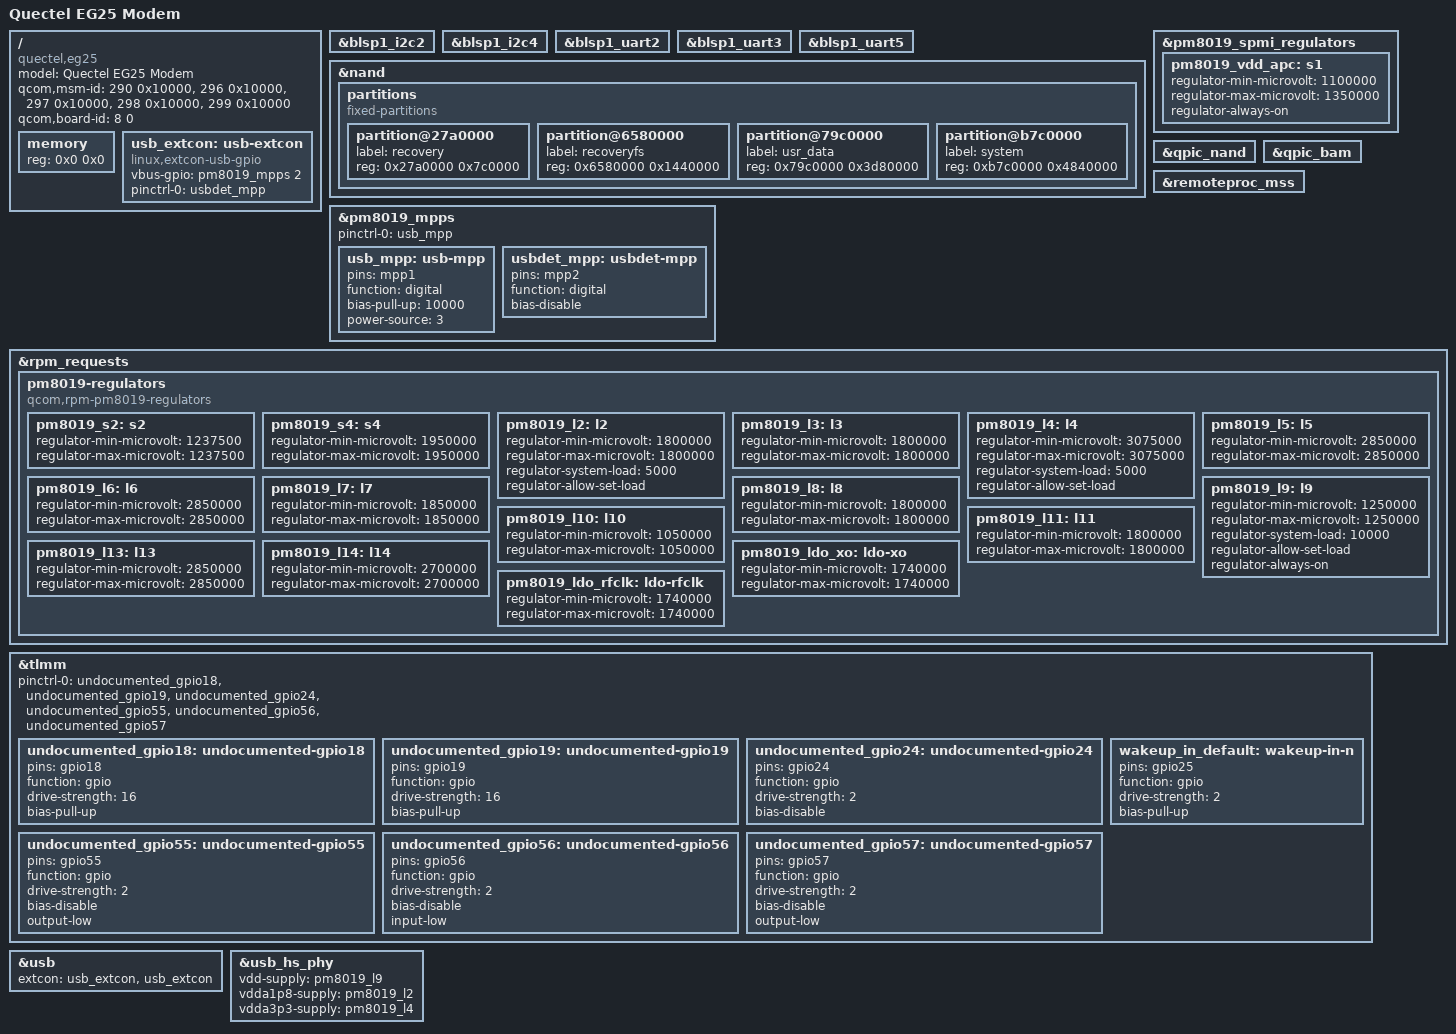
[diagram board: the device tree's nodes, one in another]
// SPDX-License-Identifier: GPL-2.0
/*
 * Copyright (c) 2020, Konrad Dybcio <konrad.dybcio@somainline.org>
 */
#include "qcom-mdm9607.dtsi"
#include "qcom-pm8019.dtsi"
#include <dt-bindings/gpio/gpio.h>
#include <dt-bindings/input/input.h>
#include <dt-bindings/pinctrl/qcom,pmic-gpio.h>

/ {
	model = "Quectel EG25 Modem";
	compatible = "quectel,eg25", "qcom,mdm9607";
	qcom,msm-id = <290 0x10000>, <296 0x10000>, <297 0x10000>, <298 0x10000>, <299 0x10000>;
	qcom,board-id = <8 0>;

	memory {
		device_type = "memory";
		reg = <0x0 0x0>;
	};

	usb_extcon: usb-extcon {
		compatible = "linux,extcon-usb-gpio";
		vbus-gpio = <&pm8019_mpps 2 GPIO_ACTIVE_HIGH>;
		pinctrl-names = "default";
		pinctrl-0 = <&usbdet_mpp>;
	};
};

&blsp1_i2c2 {
	status = "okay";
};

&blsp1_i2c4 {
	status = "okay";

	/delete-property/ pinctrl-names;
	/delete-property/ pinctrl-0;
};

&blsp1_uart2 {
	status = "okay";
};

&blsp1_uart3 {
	status = "okay";
};

/* Debug UART */
&blsp1_uart5 {
	status = "okay";
};

&nand {
	partitions {
		compatible = "fixed-partitions";
		#address-cells = <1>;
		#size-cells = <1>;

		partition@27a0000 {
			label = "recovery";
			reg = <0x27a0000 0x7c0000>;
		};

		partition@6580000 {
			label = "recoveryfs";
			reg = <0x6580000 0x1440000>;
		};

		partition@79c0000 {
			label = "usr_data";
			reg = <0x79c0000 0x3d80000>;
		};

		partition@b7c0000 {
			label = "system";
			reg = <0xb7c0000 0x4840000>;
		};
	};
};

&pm8019_mpps {
	pinctrl-names = "default";
	pinctrl-0 = <&usb_mpp>;

	usb_mpp: usb-mpp {
		pins = "mpp1";
		function = "digital";
		bias-pull-up = <10000>;

		power-source = <3>; /* 1.8V (L11) */
	};

	usbdet_mpp: usbdet-mpp {
		pins = "mpp2";
		function = "digital";
		bias-disable;
	};
};

&pm8019_spmi_regulators {
	pm8019_vdd_apc: s1 {
		/*
		 * This regulator has a minimum voltage of
		 * 1050uV on this board, but it has the "normal
		 * idle" value pinned at 1100uV and since undervolting
		 * the CPU all the time isn't generally a wise idea, pin
		 * it at 1100uV until we have proper voltage management.
		 */
		regulator-min-microvolt = <1100000>;
		regulator-max-microvolt = <1350000>;
		regulator-always-on; /* We should never let the CPU unplug itself! */
	};
};

/* NAND ID: 0x1590aaad | 256MiB | 4-bit ECC */
&qpic_nand {
	status = "okay";
};

&qpic_bam {
	status = "okay";
};

&remoteproc_mss {
	status = "okay";
};

&rpm_requests {
	pm8019-regulators {
		compatible = "qcom,rpm-pm8019-regulators";

		/* S1 is managed by CPR over SPMI */

		pm8019_s2: s2 {
			regulator-min-microvolt = <1237500>; //750000
			regulator-max-microvolt = <1237500>;
		};

		/* S3 is managed by RPMPD */

		pm8019_s4: s4 {
			regulator-min-microvolt = <1950000>; //1800000
			regulator-max-microvolt = <1950000>;
		};

		/* L1 seems inaccessible from SPMI? 1250000-1250000 uV */

		pm8019_l2: l2 {
			regulator-min-microvolt = <1800000>;
			regulator-max-microvolt = <1800000>;
			regulator-system-load = <5000>;
			regulator-allow-set-load;
		};

		pm8019_l3: l3 {
			regulator-min-microvolt = <1800000>;
			regulator-max-microvolt = <1800000>;
		};

		pm8019_l4: l4 {
			regulator-min-microvolt = <3075000>;
			regulator-max-microvolt = <3075000>;
			regulator-system-load = <5000>;
			regulator-allow-set-load;
		};

		pm8019_l5: l5 {
			regulator-min-microvolt = <2850000>; //1700000
			regulator-max-microvolt = <2850000>;
		};

		pm8019_l6: l6 {
			regulator-min-microvolt = <2850000>; //1700000
			regulator-max-microvolt = <2850000>;
		};

		pm8019_l7: l7 {
			regulator-min-microvolt = <1850000>; //1700000
			regulator-max-microvolt = <1850000>;
		};

		pm8019_l8: l8 {
			regulator-min-microvolt = <1800000>;
			regulator-max-microvolt = <1800000>;
		};

		/* L9 seems inaccessible from SPMI? 1200000-1250000 uV */
		pm8019_l9: l9 {
			regulator-min-microvolt = <1250000>;
			regulator-max-microvolt = <1250000>;
			regulator-system-load = <10000>;
			regulator-allow-set-load;
			regulator-always-on;
		};

		/* L10 seems inaccessible from SPMI? 1050000-1050000 uV */
		pm8019_l10: l10 {
			regulator-min-microvolt = <1050000>;
			regulator-max-microvolt = <1050000>;
		};

		pm8019_l11: l11 {
			regulator-min-microvolt = <1800000>;
			regulator-max-microvolt = <1800000>;
		};

		/* L12 is managed by RPMPD */

		pm8019_l13: l13 {
			regulator-min-microvolt = <2850000>; //1800000
			regulator-max-microvolt = <2850000>;
		};

		pm8019_l14: l14 {
			regulator-min-microvolt = <2700000>; //2650000
			regulator-max-microvolt = <2700000>;
		};

		/*
		 * These two are theoretically managed by SPMI
		 * and theoretically disabled over there, but they
		 * are up in LK, so let's vote for them here too.
		 */

		pm8019_ldo_xo: ldo-xo {
			regulator-min-microvolt = <1740000>;
			regulator-max-microvolt = <1740000>;
		};

		pm8019_ldo_rfclk: ldo-rfclk {
			regulator-min-microvolt = <1740000>;
			regulator-max-microvolt = <1740000>;
		};
	};
};

&tlmm {
	pinctrl-names = "default";
	pinctrl-0 = <&undocumented_gpio18 &undocumented_gpio19 &undocumented_gpio24
			&undocumented_gpio55 &undocumented_gpio56 &undocumented_gpio57>;

	undocumented_gpio18: undocumented-gpio18 {
		pins = "gpio18";
		function = "gpio";
		drive-strength = <16>;
		bias-pull-up;
	};

	undocumented_gpio19: undocumented-gpio19 {
		pins = "gpio19";
		function = "gpio";
		drive-strength = <16>;
		bias-pull-up;
	};

	undocumented_gpio24: undocumented-gpio24 {
		pins = "gpio24";
		function = "gpio";
		drive-strength = <2>;
		bias-disable;
	};

	wakeup_in_default: wakeup-in-n {
		pins = "gpio25";
		function = "gpio";
		drive-strength = <2>;
		bias-pull-up;
	};

	undocumented_gpio55: undocumented-gpio55 {
		pins = "gpio55";
		function = "gpio";
		drive-strength = <2>;
		bias-disable;
		output-low;
	};

	undocumented_gpio56: undocumented-gpio56 {
		pins = "gpio56";
		function = "gpio";
		drive-strength = <2>;
		bias-disable;
		input-low;
	};

	undocumented_gpio57: undocumented-gpio57 {
		pins = "gpio57";
		function = "gpio";
		drive-strength = <2>;
		bias-disable;
		output-low;
	};
};

&usb {
	status = "okay";
	extcon = <&usb_extcon>, <&usb_extcon>;
};

&usb_hs_phy {
	status = "okay";

	vdd-supply = <&pm8019_l9>;
	vdda1p8-supply = <&pm8019_l2>;
	vdda3p3-supply = <&pm8019_l4>;
};
